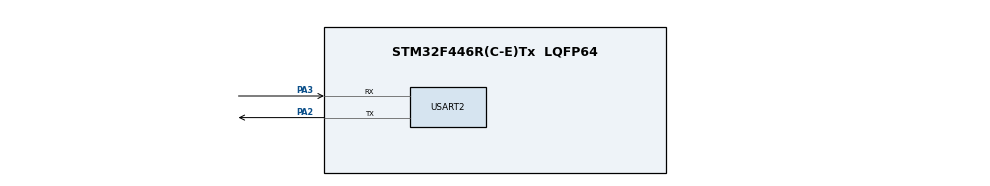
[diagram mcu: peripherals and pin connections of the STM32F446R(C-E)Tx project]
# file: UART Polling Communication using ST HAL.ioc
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Mcu.Family=STM32F4
Mcu.Name=STM32F446R(C-E)Tx
Mcu.Package=LQFP64
NVIC.PriorityGroup=NVIC_PRIORITYGROUP_4
PA2.Mode=Asynchronous
PA2.Signal=USART2_TX
PA3.Mode=Asynchronous
PA3.Signal=USART2_RX
ProjectManager.HeapSize=0x200
ProjectManager.StackSize=0x400
ProjectManager.TargetToolchain=STM32CubeIDE
RCC.CortexFreq_Value=16000000
RCC.USBFreq_Value=96000000
RCC.VCOOutputFreq_Value=192000000
USART2.VirtualMode=VM_ASYNC
board=custom

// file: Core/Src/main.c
/* USER CODE BEGIN Header */
/**
  ******************************************************************************
  * @file           : main.c
  * @brief          : Main program body
  ******************************************************************************
  * @attention
  *
  * Copyright (c) 2025 STMicroelectronics.
  * All rights reserved.
  *
  * This software is licensed under terms that can be found in the LICENSE file
  * in the root directory of this software component.
  * If no LICENSE file comes with this software, it is provided AS-IS.
  *
  ******************************************************************************
  */
/* USER CODE END Header */
#include "main.h"

/* USER CODE BEGIN Includes */
#include <stdio.h>
#include <string.h>
#include <stdlib.h>
#include  "stm32f4xx_hal.h"

/* USER CODE END Includes */

UART_HandleTypeDef huart2;

/* USER CODE BEGIN PV */

char userData[1];
volatile uint8_t ready = 0;

/* USER CODE END PV */

void SystemClock_Config(void);
static void MX_GPIO_Init(void);
static void MX_USART2_UART_Init(void);

/* USER CODE BEGIN 0 */
void printMsg(void)
{
             char *msgs[] = {"WELCOME! \n",  " This is the main menu! \n ",  " Enter a number : \n"};

             for(int i = 0; i < 3; i++)
             {
            	   HAL_UART_Transmit_IT(&huart2, (uint8_t *)msgs[i], strlen(msgs[i]));
            	   HAL_Delay(1000);
             }

}

int8_t userChoice(void)
{
                if(ready == 1)
                {
                	  ready = 0;
                	  return atoi(userData);
                }
                return -1;
}

void USART2_IRQHandler(void)
{
       HAL_UART_IRQHandler(&huart2);
}

void HAL_UART_RxCpltCallback(UART_HandleTypeDef *UartHandle)
{
           if(UartHandle->Instance == USART2)
           {
        	         HAL_UART_Transmit(&huart2, (uint8_t *)"RECEIVED!\n", strlen("RECEIVED!\n"), 100);
        	         HAL_GPIO_TogglePin(GPIOA, GPIO_PIN_5);
        	         ready = 1;
        	         HAL_UART_Receive_IT(&huart2, (uint8_t *)userData, 1);
           }
}

void HAL_UART_TxCpltCallback(UART_HandleTypeDef * UartHandle)
{
                 	  if(UartHandle->Instance == USART2)
                 	  {
                 		        HAL_UART_Transmit(&huart2, (uint8_t *)"SENT!\n", strlen("SENT!\n"), 100);
                 	  }
}

void processChoice(uint8_t choice)
{
        char msg[50];

        if(choice > 3 || choice < 0)
                        return;

        sprintf(msg, "%d", choice);
        HAL_UART_Transmit_IT(&huart2, (uint8_t *)msg, strlen(msg));

        switch(choice)
        {
               case 1:
            	    HAL_GPIO_TogglePin(GPIOA, GPIO_PIN_5);
            	    HAL_UART_Transmit_IT(&huart2, (uint8_t *)"Toggled!\n",  strlen("Toggled!\n"));
            	    break;
               case 2:
            	    sprintf(msg, "\r\n USER Button status: %s", HAL_GPIO_ReadPin(GPIOC, GPIO_PIN_13) == 0 ? "PRESSED" : "RELEASED");
            	    HAL_UART_Transmit_IT(&huart2, (uint8_t *)msg, strlen(msg));
            	    break;
               case 3:
            	    return;
        }
}

void doSomethingImportant(void)
{
                HAL_Delay(1000);
                HAL_GPIO_TogglePin(GPIOA, GPIO_PIN_5);
}

/* USER CODE END 0 */

int main(void)
{

  /* MCU Configuration--------------------------------------------------------*/

  /* Reset of all peripherals, Initializes the Flash interface and the Systick. */
  HAL_Init();

  /* Configure the system clock */
  SystemClock_Config();
  MX_GPIO_Init();
  MX_USART2_UART_Init();

  /* USER CODE BEGIN SysInit */
  HAL_NVIC_EnableIRQ(USART2_IRQn);
  HAL_NVIC_SetPriority(USART2_IRQn, 0, 0);

  /*Let's enable the receiving interrupt*/
  HAL_UART_Receive_IT(&huart2, (uint8_t *)userData, 1);
  /* USER CODE END SysInit */

  /* USER CODE BEGIN 2 */

  __HAL_RCC_GPIOA_CLK_ENABLE();
  __HAL_RCC_GPIOC_CLK_ENABLE();
  GPIO_InitTypeDef GPIO_InitStruct = {0};

  GPIO_InitStruct.Pin = GPIO_PIN_5;
  GPIO_InitStruct.Mode = GPIO_MODE_OUTPUT_PP;
  GPIO_InitStruct.Pull = GPIO_NOPULL;
  GPIO_InitStruct.Speed = GPIO_SPEED_FREQ_LOW;
  HAL_GPIO_Init(GPIOA, &GPIO_InitStruct);

  GPIO_InitStruct.Pin = GPIO_PIN_13;
  GPIO_InitStruct.Mode = GPIO_MODE_INPUT;
  GPIO_InitStruct.Pull = GPIO_NOPULL;
  GPIO_InitStruct.Speed = GPIO_SPEED_FREQ_LOW;
  HAL_GPIO_Init(GPIOC, &GPIO_InitStruct);

  printMessage:
        printMsg();

  /* USER CODE END 2 */

  /* Infinite loop */
  /* USER CODE BEGIN WHILE */
  while (1)
  {
	 if(ready)
	 {
		      int choice = userChoice();
		      if(choice > 0)
		      {
		    	     processChoice(choice);
		    	     if(choice == 3)
		    	    	      goto printMessage;
		      }
	 }

	 doSomethingImportant();

    /* USER CODE END WHILE */

  }
}

void SystemClock_Config(void)
{
  RCC_OscInitTypeDef RCC_OscInitStruct = {0};
  RCC_ClkInitTypeDef RCC_ClkInitStruct = {0};

  /** Configure the main internal regulator output voltage
  */
  __HAL_RCC_PWR_CLK_ENABLE();
  __HAL_PWR_VOLTAGESCALING_CONFIG(PWR_REGULATOR_VOLTAGE_SCALE3);

  /** Initializes the RCC Oscillators according to the specified parameters
  * in the RCC_OscInitTypeDef structure.
  */
  RCC_OscInitStruct.OscillatorType = RCC_OSCILLATORTYPE_HSI;
  RCC_OscInitStruct.HSIState = RCC_HSI_ON;
  RCC_OscInitStruct.HSICalibrationValue = RCC_HSICALIBRATION_DEFAULT;
  RCC_OscInitStruct.PLL.PLLState = RCC_PLL_NONE;
  if (HAL_RCC_OscConfig(&RCC_OscInitStruct) != HAL_OK)
  {
    Error_Handler();
  }

  /** Initializes the CPU, AHB and APB buses clocks
  */
  RCC_ClkInitStruct.ClockType = RCC_CLOCKTYPE_HCLK|RCC_CLOCKTYPE_SYSCLK
                              |RCC_CLOCKTYPE_PCLK1|RCC_CLOCKTYPE_PCLK2;
  RCC_ClkInitStruct.SYSCLKSource = RCC_SYSCLKSOURCE_HSI;
  RCC_ClkInitStruct.AHBCLKDivider = RCC_SYSCLK_DIV1;
  RCC_ClkInitStruct.APB1CLKDivider = RCC_HCLK_DIV1;
  RCC_ClkInitStruct.APB2CLKDivider = RCC_HCLK_DIV1;

  if (HAL_RCC_ClockConfig(&RCC_ClkInitStruct, FLASH_LATENCY_0) != HAL_OK)
  {
    Error_Handler();
  }
}

static void MX_USART2_UART_Init(void)
{

  huart2.Instance = USART2;
  huart2.Init.BaudRate = 115200;
  huart2.Init.WordLength = UART_WORDLENGTH_8B;
  huart2.Init.StopBits = UART_STOPBITS_1;
  huart2.Init.Parity = UART_PARITY_NONE;
  huart2.Init.Mode = UART_MODE_TX_RX;
  huart2.Init.HwFlowCtl = UART_HWCONTROL_NONE;
  huart2.Init.OverSampling = UART_OVERSAMPLING_16;
  if (HAL_UART_Init(&huart2) != HAL_OK)
  {
    Error_Handler();
  }

}

static void MX_GPIO_Init(void)
{

  /* GPIO Ports Clock Enable */
  __HAL_RCC_GPIOA_CLK_ENABLE();

}

void Error_Handler(void)
{
  __disable_irq();
  while (1)
  {
  }
}
